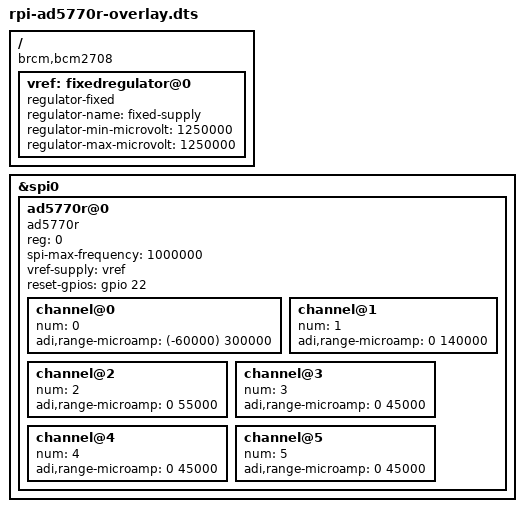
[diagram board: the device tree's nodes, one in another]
/dts-v1/;
/plugin/;

/ {
	compatible = "brcm,bcm2708";

	fragment@0 {
		target = <&spi0>;
		__overlay__ {
			#address-cells = <1>;
			#size-cells = <0>;
			status = "okay";

			ad5770r@0 {
				compatible = "ad5770r";
				reg = <0>;
				spi-max-frequency = <1000000>;
				vref-supply = <&vref>;

				reset-gpios = <&gpio 22 0>;

				channel@0 {
					num = <0>;
					adi,range-microamp = <(-60000) 300000>;
				};

				channel@1 {
					num = <1>;
					adi,range-microamp = <0 140000>;
				};

				channel@2 {
					num = <2>;
					adi,range-microamp = <0 55000>;
				};

				channel@3 {
					num = <3>;
					adi,range-microamp = <0 45000>;
				};

				channel@4 {
					num = <4>;
					adi,range-microamp = <0 45000>;
				};

				channel@5 {
					num = <5>;
					adi,range-microamp = <0 45000>;
				};
			};
		};
	};

	fragment@1 {
		target-path = "/";
		__overlay__ {
		vref: fixedregulator@0 {
				compatible = "regulator-fixed";
				regulator-name = "fixed-supply";
				regulator-min-microvolt = <1250000>;
				regulator-max-microvolt = <1250000>;
			};
		};
	};
};
